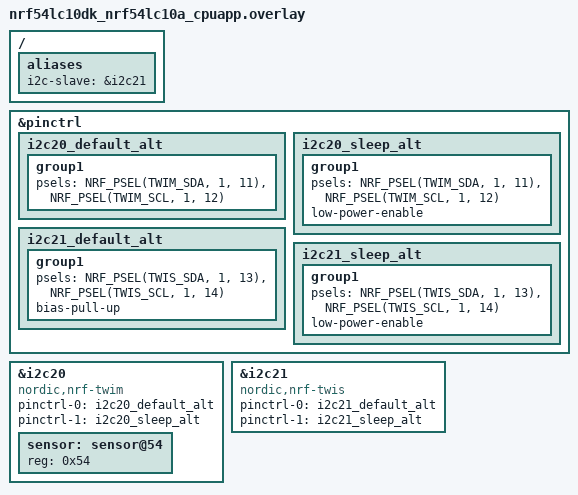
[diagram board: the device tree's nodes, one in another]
/*
 * Two loopbacks are required
 * (nRF54LC10 DK: avoid P1.8 — button2 / GRTC fast clock; P1.9 — button1):
 * P1.11 - P1.13 (SDA)
 * P1.12 - P1.14 (SCL)
 */

/ {
	aliases {
		i2c-slave = &i2c21;
	};
};

&pinctrl {
	i2c20_default_alt: i2c20_default_alt {
		group1 {
			psels = <NRF_PSEL(TWIM_SDA, 1, 11)>,
				<NRF_PSEL(TWIM_SCL, 1, 12)>;
		};
	};

	i2c20_sleep_alt: i2c20_sleep_alt {
		group1 {
			psels = <NRF_PSEL(TWIM_SDA, 1, 11)>,
				<NRF_PSEL(TWIM_SCL, 1, 12)>;
			low-power-enable;
		};
	};

	i2c21_default_alt: i2c21_default_alt {
		group1 {
			psels = <NRF_PSEL(TWIS_SDA, 1, 13)>,
				<NRF_PSEL(TWIS_SCL, 1, 14)>;
			bias-pull-up;
		};
	};

	i2c21_sleep_alt: i2c21_sleep_alt {
		group1 {
			psels = <NRF_PSEL(TWIS_SDA, 1, 13)>,
				<NRF_PSEL(TWIS_SCL, 1, 14)>;
			low-power-enable;
		};
	};
};

&i2c20 {
	compatible = "nordic,nrf-twim";
	status = "okay";
	pinctrl-0 = <&i2c20_default_alt>;
	pinctrl-1 = <&i2c20_sleep_alt>;
	pinctrl-names = "default", "sleep";

	sensor: sensor@54 {
		reg = <0x54>;
	};
};

&i2c21 {
	compatible = "nordic,nrf-twis";
	status = "okay";
	pinctrl-0 = <&i2c21_default_alt>;
	pinctrl-1 = <&i2c21_sleep_alt>;
	pinctrl-names = "default", "sleep";
};
